# ESP32C3 register map
File version: 1.0
CPU: RISC-V RV32IMC single-core 1, little endian, no MPU, FPU, 3 interrupt priority bits
Registers are 32-bit, read-write, reset 0x0 unless marked. A register's access mark holds for its fields unless they carry their own. Offsets are from the block's base; [hi:lo] are bit positions; {n}, {i} and the like mark numbered series.

## GPIO
Base 0x60004000
0x00 GPIO_BT_SELECT
  [31:0] GPIO_BT_SEL
0x04 GPIO_OUT
  [25:0] GPIO_OUT_DATA
0x08 GPIO_OUT_W1TS wo
  [25:0] GPIO_OUT_W1TS
0x0C GPIO_OUT_W1TC wo
  [25:0] GPIO_OUT_W1TC
0x1C GPIO_SDIO_SELECT
  [7:0] GPIO_SDIO_SEL
0x20 GPIO_ENABLE
  [25:0] GPIO_ENABLE_DATA
0x24 GPIO_ENABLE_W1TS wo
  [25:0] GPIO_ENABLE_W1TS
0x28 GPIO_ENABLE_W1TC wo
  [25:0] GPIO_ENABLE_W1TC
0x38 GPIO_STRAP ro
  [15:0] GPIO_STRAPPING
0x3C GPIO_IN ro
  [25:0] GPIO_IN_DATA
0x44 GPIO_STATUS
  [25:0] GPIO_STATUS_INT
0x48 GPIO_STATUS_W1TS wo
  [25:0] GPIO_STATUS_W1TS
0x4C GPIO_STATUS_W1TC wo
  [25:0] GPIO_STATUS_W1TC
0x5C GPIO_PCPU_INT ro
  [25:0] GPIO_PROCPU_INT
0x60 GPIO_PCPU_NMI_INT ro
  [25:0] GPIO_PROCPU_NMI_INT
0x64 GPIO_CPUSDIO_INT ro
  [25:0] GPIO_SDIO_INT
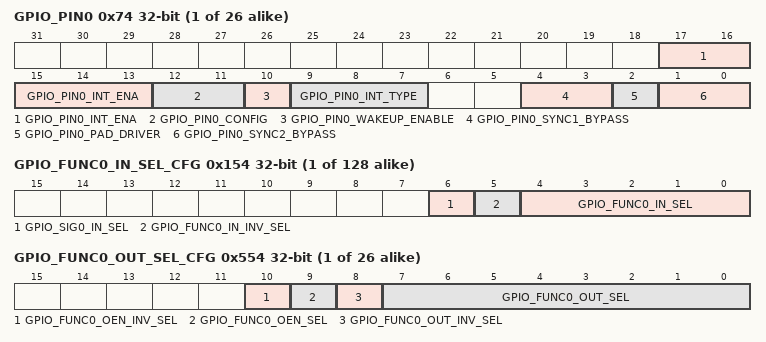
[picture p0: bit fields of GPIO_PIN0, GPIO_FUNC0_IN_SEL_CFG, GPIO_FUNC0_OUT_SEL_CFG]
{0x74+4i} GPIO_PIN{i} (i=0..25)
  [17:13] GPIO_PIN{i}_INT_ENA, [12:11] GPIO_PIN{i}_CONFIG, [10] GPIO_PIN{i}_WAKEUP_ENABLE, [9:7] GPIO_PIN{i}_INT_TYPE, [4:3] GPIO_PIN{i}_SYNC1_BYPASS, [2] GPIO_PIN{i}_PAD_DRIVER, [1:0] GPIO_PIN{i}_SYNC2_BYPASS
0x14C GPIO_STATUS_NEXT ro
  [25:0] GPIO_STATUS_INTERRUPT_NEXT
{0x154+4i} GPIO_FUNC{i}_IN_SEL_CFG (i=0..127)
  [6] GPIO_SIG{i}_IN_SEL, [5] GPIO_FUNC{i}_IN_INV_SEL, [4:0] GPIO_FUNC{i}_IN_SEL
{0x554+4i} GPIO_FUNC{i}_OUT_SEL_CFG (i=0..25)
  [10] GPIO_FUNC{i}_OEN_INV_SEL, [9] GPIO_FUNC{i}_OEN_SEL, [8] GPIO_FUNC{i}_OUT_INV_SEL, [7:0] GPIO_FUNC{i}_OUT_SEL
0x62C GPIO_CLOCK_GATE
  [0] GPIO_CLK_EN
0x6FC GPIO_DATE
  [27:0] GPIO_DATE

## GPIO_SD
Base 0x00000000
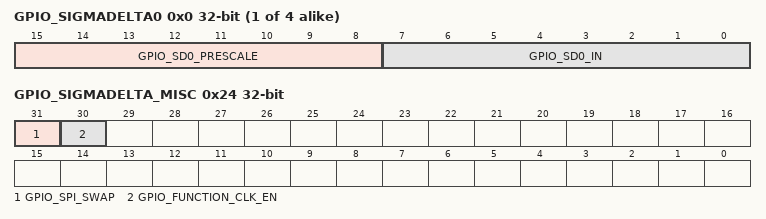
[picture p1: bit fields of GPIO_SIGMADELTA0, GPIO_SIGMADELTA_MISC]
{0x0+4i} GPIO_SIGMADELTA{i} (i=0..3)
  [15:8] GPIO_SD{i}_PRESCALE, [7:0] GPIO_SD{i}_IN
0x20 GPIO_SIGMADELTA_CG
  [31] GPIO_SD_CLK_EN
0x24 GPIO_SIGMADELTA_MISC
  [31] GPIO_SPI_SWAP, [30] GPIO_FUNCTION_CLK_EN
0x28 GPIO_SIGMADELTA_VERSION
  [27:0] GPIO_SD_DATE

## LEDC
Base 0x60019000
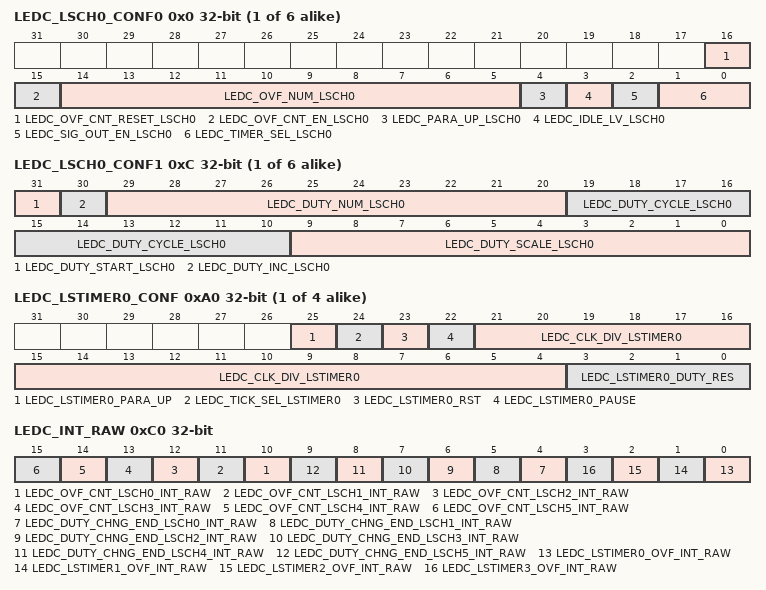
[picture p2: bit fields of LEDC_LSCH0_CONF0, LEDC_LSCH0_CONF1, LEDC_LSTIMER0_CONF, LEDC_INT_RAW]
{0x0+0x14*i} LEDC_LSCH{i}_CONF0 access per field (i=0..5)
  [16] LEDC_OVF_CNT_RESET_LSCH{i} wo, [15] LEDC_OVF_CNT_EN_LSCH{i} rw, [14:5] LEDC_OVF_NUM_LSCH{i} rw, [4] LEDC_PARA_UP_LSCH{i} wo, [3] LEDC_IDLE_LV_LSCH{i} rw, [2] LEDC_SIG_OUT_EN_LSCH{i} rw, [1:0] LEDC_TIMER_SEL_LSCH{i} rw
{0x4+0x14*i} LEDC_LSCH{i}_HPOINT (i=0..5)
  [13:0] LEDC_HPOINT_LSCH{i}
{0x8+0x14*i} LEDC_LSCH{i}_DUTY (i=0..5)
  [18:0] LEDC_DUTY_LSCH{i}
{0xC+0x14*i} LEDC_LSCH{i}_CONF1 (i=0..5)
  [31] LEDC_DUTY_START_LSCH{i}, [30] LEDC_DUTY_INC_LSCH{i}, [29:20] LEDC_DUTY_NUM_LSCH{i}, [19:10] LEDC_DUTY_CYCLE_LSCH{i}, [9:0] LEDC_DUTY_SCALE_LSCH{i}
{0x10+0x14*i} LEDC_LSCH{i}_DUTY_R ro (i=0..5)
  [18:0] LEDC_DUTY_LSCH{i}
{0xA0+8i} LEDC_LSTIMER{i}_CONF access per field (i=0..3)
  [25] LEDC_LSTIMER{i}_PARA_UP wo, [24] LEDC_TICK_SEL_LSTIMER{i} rw, [23] LEDC_LSTIMER{i}_RST rw, [22] LEDC_LSTIMER{i}_PAUSE rw, [21:4] LEDC_CLK_DIV_LSTIMER{i} rw, [3:0] LEDC_LSTIMER{i}_DUTY_RES rw
{0xA4+8i} LEDC_LSTIMER{i}_VALUE ro (i=0..3)
  [13:0] LEDC_LSTIMER{i}_CNT
0xC0 LEDC_INT_RAW ro
  [n+10] LEDC_OVF_CNT_LSCH{n}_INT_RAW (n=0..5), [n+4] LEDC_DUTY_CHNG_END_LSCH{n}_INT_RAW (n=0..5), [n] LEDC_LSTIMER{n}_OVF_INT_RAW (n=0..3)
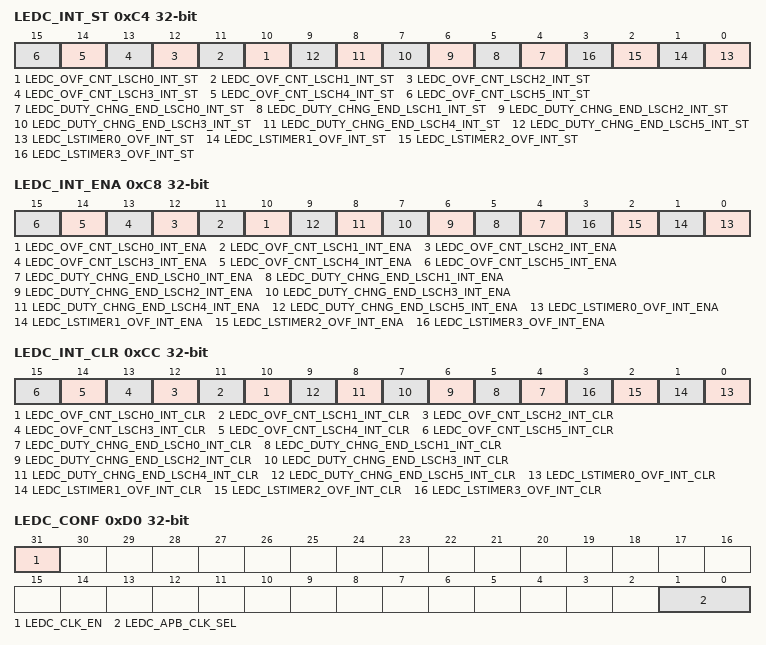
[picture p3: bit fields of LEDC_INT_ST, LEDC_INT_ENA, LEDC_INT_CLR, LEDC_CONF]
0xC4 LEDC_INT_ST ro
  [n+10] LEDC_OVF_CNT_LSCH{n}_INT_ST (n=0..5), [n+4] LEDC_DUTY_CHNG_END_LSCH{n}_INT_ST (n=0..5), [n] LEDC_LSTIMER{n}_OVF_INT_ST (n=0..3)
0xC8 LEDC_INT_ENA
  [n+10] LEDC_OVF_CNT_LSCH{n}_INT_ENA (n=0..5), [n+4] LEDC_DUTY_CHNG_END_LSCH{n}_INT_ENA (n=0..5), [n] LEDC_LSTIMER{n}_OVF_INT_ENA (n=0..3)
0xCC LEDC_INT_CLR wo
  [n+10] LEDC_OVF_CNT_LSCH{n}_INT_CLR (n=0..5), [n+4] LEDC_DUTY_CHNG_END_LSCH{n}_INT_CLR (n=0..5), [n] LEDC_LSTIMER{n}_OVF_INT_CLR (n=0..3)
0xD0 LEDC_CONF
  [31] LEDC_CLK_EN, [1:0] LEDC_APB_CLK_SEL
0xFC LEDC_DATE

## RTC_I2C
Base 0x6000E000
0x00 RTC_I2C_SCL_LOW_PERIOD
  [19:0] RTC_I2C_SCL_LOW_PERIOD
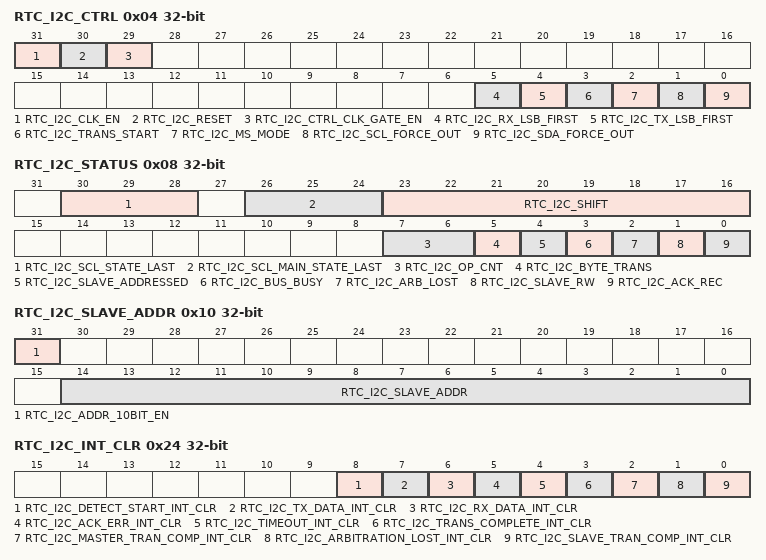
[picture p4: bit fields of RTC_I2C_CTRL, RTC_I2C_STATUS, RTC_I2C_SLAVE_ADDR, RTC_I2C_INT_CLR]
0x04 RTC_I2C_CTRL
  [31] RTC_I2C_CLK_EN, [30] RTC_I2C_RESET, [29] RTC_I2C_CTRL_CLK_GATE_EN, [5] RTC_I2C_RX_LSB_FIRST, [4] RTC_I2C_TX_LSB_FIRST, [3] RTC_I2C_TRANS_START, [2] RTC_I2C_MS_MODE, [1] RTC_I2C_SCL_FORCE_OUT, [0] RTC_I2C_SDA_FORCE_OUT
0x08 RTC_I2C_STATUS ro
  [30:28] RTC_I2C_SCL_STATE_LAST, [26:24] RTC_I2C_SCL_MAIN_STATE_LAST, [23:16] RTC_I2C_SHIFT, [7:6] RTC_I2C_OP_CNT, [5] RTC_I2C_BYTE_TRANS, [4] RTC_I2C_SLAVE_ADDRESSED, [3] RTC_I2C_BUS_BUSY, [2] RTC_I2C_ARB_LOST, [1] RTC_I2C_SLAVE_RW, [0] RTC_I2C_ACK_REC
0x0C RTC_I2C_TIMEOUT
  [19:0] RTC_I2C_TIMEOUT
0x10 RTC_I2C_SLAVE_ADDR
  [31] RTC_I2C_ADDR_10BIT_EN, [14:0] RTC_I2C_SLAVE_ADDR
0x14 RTC_I2C_SCL_HIGH
  [19:0] RTC_I2C_SCL_HIGH_PERIOD
0x18 RTC_I2C_SDA_DUTY
  [19:0] RTC_I2C_SDA_DUTY_NUM
0x1C RTC_I2C_SCL_START_PERIOD
  [19:0] RTC_I2C_SCL_START_PERIOD
0x20 RTC_I2C_SCL_STOP_PERIOD
  [19:0] RTC_I2C_SCL_STOP_PERIOD
0x24 RTC_I2C_INT_CLR wo
  [8] RTC_I2C_DETECT_START_INT_CLR, [7] RTC_I2C_TX_DATA_INT_CLR, [6] RTC_I2C_RX_DATA_INT_CLR, [5] RTC_I2C_ACK_ERR_INT_CLR, [4] RTC_I2C_TIMEOUT_INT_CLR, [3] RTC_I2C_TRANS_COMPLETE_INT_CLR, [2] RTC_I2C_MASTER_TRAN_COMP_INT_CLR, [1] RTC_I2C_ARBITRATION_LOST_INT_CLR, [0] RTC_I2C_SLAVE_TRAN_COMP_INT_CLR
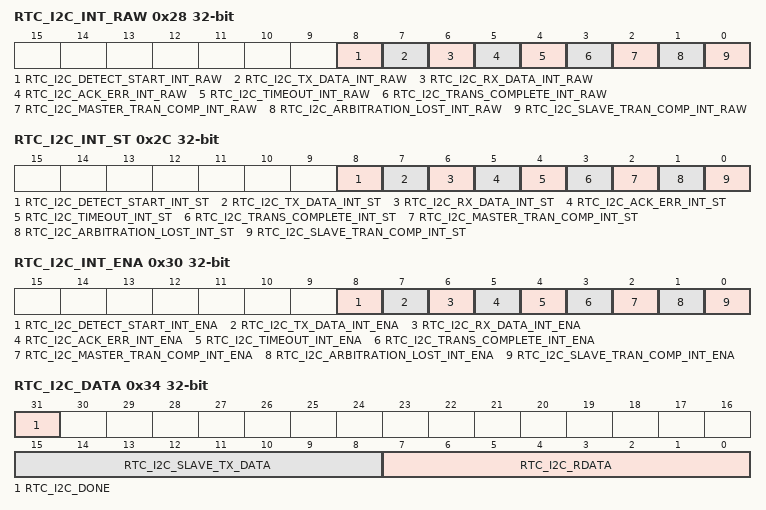
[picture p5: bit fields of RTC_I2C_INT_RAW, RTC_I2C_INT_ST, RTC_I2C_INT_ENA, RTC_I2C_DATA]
0x28 RTC_I2C_INT_RAW ro
  [8] RTC_I2C_DETECT_START_INT_RAW, [7] RTC_I2C_TX_DATA_INT_RAW, [6] RTC_I2C_RX_DATA_INT_RAW, [5] RTC_I2C_ACK_ERR_INT_RAW, [4] RTC_I2C_TIMEOUT_INT_RAW, [3] RTC_I2C_TRANS_COMPLETE_INT_RAW, [2] RTC_I2C_MASTER_TRAN_COMP_INT_RAW, [1] RTC_I2C_ARBITRATION_LOST_INT_RAW, [0] RTC_I2C_SLAVE_TRAN_COMP_INT_RAW
0x2C RTC_I2C_INT_ST ro
  [8] RTC_I2C_DETECT_START_INT_ST, [7] RTC_I2C_TX_DATA_INT_ST, [6] RTC_I2C_RX_DATA_INT_ST, [5] RTC_I2C_ACK_ERR_INT_ST, [4] RTC_I2C_TIMEOUT_INT_ST, [3] RTC_I2C_TRANS_COMPLETE_INT_ST, [2] RTC_I2C_MASTER_TRAN_COMP_INT_ST, [1] RTC_I2C_ARBITRATION_LOST_INT_ST, [0] RTC_I2C_SLAVE_TRAN_COMP_INT_ST
0x30 RTC_I2C_INT_ENA
  [8] RTC_I2C_DETECT_START_INT_ENA, [7] RTC_I2C_TX_DATA_INT_ENA, [6] RTC_I2C_RX_DATA_INT_ENA, [5] RTC_I2C_ACK_ERR_INT_ENA, [4] RTC_I2C_TIMEOUT_INT_ENA, [3] RTC_I2C_TRANS_COMPLETE_INT_ENA, [2] RTC_I2C_MASTER_TRAN_COMP_INT_ENA, [1] RTC_I2C_ARBITRATION_LOST_INT_ENA, [0] RTC_I2C_SLAVE_TRAN_COMP_INT_ENA
0x34 RTC_I2C_DATA access per field
  [31] RTC_I2C_DONE ro, [15:8] RTC_I2C_SLAVE_TX_DATA rw, [7:0] RTC_I2C_RDATA ro
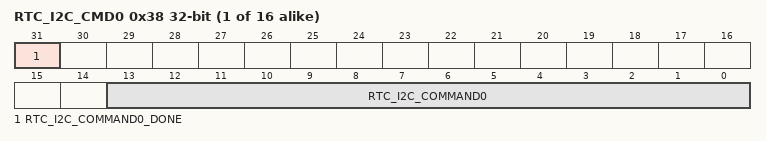
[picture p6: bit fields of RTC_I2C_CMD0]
{0x38+4i} RTC_I2C_CMD{i} access per field (i=0..15)
  [31] RTC_I2C_COMMAND{i}_DONE ro, [13:0] RTC_I2C_COMMAND{i} rw
0xFC RTC_I2C_DATE
  [27:0] RTC_I2C_DATE
